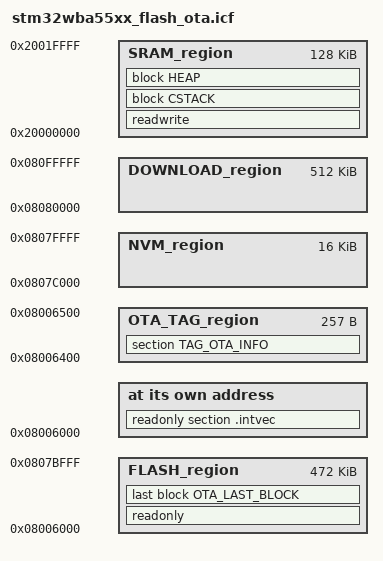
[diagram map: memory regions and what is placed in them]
/**********************************************************************************/
/**** Linker File (ICF)                                                        ****/
/**********************************************************************************/

/*-Series memory map-*/
define symbol __FLASH_BASE__              = 0x08000000;
define symbol __FLASH_TOP__               = 0x080FFFFF;
define symbol __SRAM1_BASE__              = 0x20000000;
define symbol __SRAM1_TOP__               = 0x2000FFFF;
define symbol __SRAM2_BASE__              = 0x20010000;
define symbol __SRAM2_TOP__               = 0x2001FFFF;

/*-Flash layout-*/
define symbol __region_DOWNLOAD_end__     = __FLASH_TOP__;
define symbol __region_DOWNLOAD_start__   = 0x08080000;
define symbol __region_NVM_size__         = 0x4000;
define symbol __region_NVM_end__          = __region_DOWNLOAD_start__ - 0x1;
define symbol __region_NVM_start__        = __region_NVM_end__ - __region_NVM_size__ + 0x1;
define symbol __region_FLASH_end__        = __region_NVM_start__ - 0x1;
define symbol __region_FLASH_start__      = 0x08006000;

/*-RAM layout-*/
define symbol __region_SRAM_start__       = __SRAM1_BASE__;
define symbol __region_SRAM_end__         = __SRAM2_TOP__;

/*-Stack and heap-*/
define symbol __ICFEDIT_size_heap__   = 0x10000;
define symbol __ICFEDIT_size_cstack__ = 0x1000;
define symbol __intvec_start__            = __region_FLASH_start__;

/*-Regions-*/
define memory mem with size = 4G;
define region FLASH_region      = mem:[from __region_FLASH_start__ to __region_FLASH_end__];
define region NVM_region        = mem:[from __region_NVM_start__ to __region_NVM_end__];
define region DOWNLOAD_region   = mem:[from __region_DOWNLOAD_start__ to __region_DOWNLOAD_end__];
define region SRAM_region       = mem:[from __region_SRAM_start__ to __region_SRAM_end__];
define region OTA_TAG_region    = mem:[from (__region_FLASH_start__ + 0x400) to (__region_FLASH_start__ + 0x400 + 0x100)];

/*-Blocks-*/
define block HEAP   with alignment = 8, size = __ICFEDIT_size_heap__   { };
define block CSTACK with alignment = 8, size = __ICFEDIT_size_cstack__ { };

/*-Initialization strategies-*/
initialize by copy { readwrite };
do not initialize  { section .noinit };

/*-Sections placements-*/
place at address mem:__intvec_start__ { readonly section .intvec };
keep                        { section TAG_OTA_INFO };
keep                        { section TAG_OTA_END };
keep                        { section .checksum };
define block OTA_LAST_BLOCK { section TAG_OTA_END, last section .checksum };
place in OTA_TAG_region     { section TAG_OTA_INFO };
place in NVM_region         { };
place in DOWNLOAD_region    { };
place in FLASH_region       { readonly, last block OTA_LAST_BLOCK };
place in SRAM_region        { readwrite, block CSTACK, block HEAP };
